# A31T21x register map
Vendor: ABOV Semiconductor Co., Ltd.; Series: A31T21x; File version: 1.0
CPU: CM0PLUS r0p1, little endian, no MPU, no FPU, VTOR, 2 interrupt priority bits
Registers are 32-bit, read-write, reset 0x0 unless marked. A register's access mark holds for its fields unless they carry their own. Offsets are from the block's base; [hi:lo] are bit positions.

## UART0 — UNIVERSAL ASYNCHRONOUS RECEIVER/TRANSMITTER
Base 0x40004000
Same registers: UART1 0x40004100
0x00 RBR ro — Receive Buffer Register
  [7:0] RBR — recevied/transmit data
0x00 THR wo — Transmit Data Hold Register
  [7:0] THR — recevied/transmit data
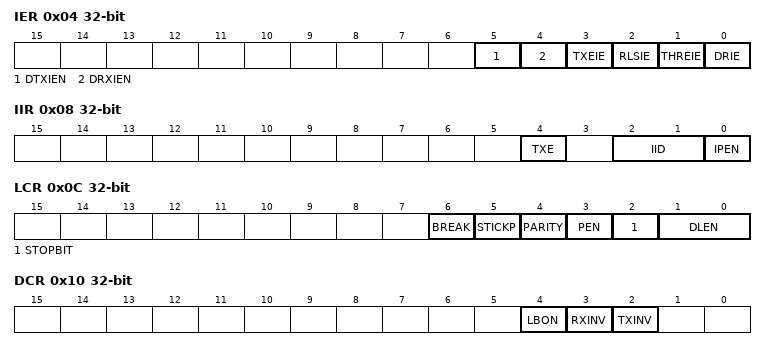
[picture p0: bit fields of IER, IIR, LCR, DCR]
0x04 IER — UART Interrupt Enable Register
  [5] DTXIEN — DMA transmit done interrupt enable
  [4] DRXIEN — DMA Receiver line status interrupt enable
  [3] TXEIE — Transmit Register Empty Interrupt Enable
  [2] RLSIE — receiver line status interrupt enable
  [1] THREIE — Transmit holding register empty interrupt enable
  [0] DRIE — Data receive interrupt enable
0x08 IIR — UART Interrupt ID Register
  [4] TXE — Interrupt source ID
  [2:1] IID — Interrupt source ID
  [0] IPEN — Interrupt pending bit
0x0C LCR — UART Line Control Register
  [6] BREAK
  [5] STICKP — STICK
  [4] PARITY
  [3] PEN — parity bit transfer enable
  [2] STOPBIT
  [1:0] DLEN — Data length in one transfer word
0x10 DCR — UART Data Control Register
  [4] LBON — Local loopback test mode enable
  [3] RXINV — Rx Data Inversion selection
  [2] TXINV — TX Data Inversion selection
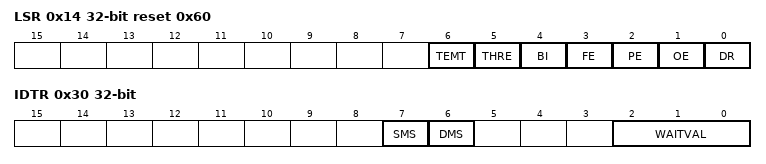
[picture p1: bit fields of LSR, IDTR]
0x14 LSR reset 0x60 — UART Line Status Register
  [6] TEMT — Transmit empty
  [5] THRE — Transmit holding register empty
  [4] BI — break condition indication bit
  [3] FE — frame error
  [2] PE — parity error
  [1] OE — overrun error
  [0] DR — Data recevied
0x20 BDR — Baud rate Divisor Latch Register
  [15:0] BDR — baudrate setting
0x24 BFR — Baud rate Fraction Counter Register
  [7:0] BFR — Fraction counter value
0x30 IDTR — Inter-frame Delay Time Register
  [7] SMS — Start Bit Multi Sampling Enable bit
  [6] DMS — Data Bit Multi sampling enable
  [2:0] WAITVAL — wait time is decied by this value

## SPI20 — Serial Peripheral Interface Bus
Base 0x40004C00
Same registers: SPI21 0x40004D00
0x00 TDR wo — SPI2 n Transmit Data Register
  [16:0] TDR — Transmit Data Bit
0x00 RDR ro — SPI n Received Data Register
  [16:0] RDR — Received Data Bit
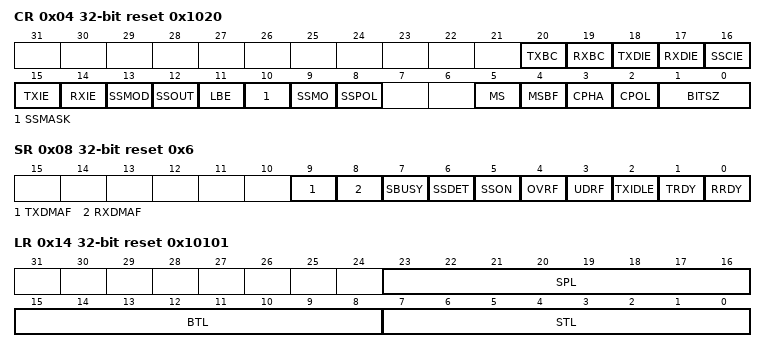
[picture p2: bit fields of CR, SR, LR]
0x04 CR reset 0x1020 — SPI Control Register
  [20] TXBC — Tx Buffer Clear Bit
  [19] RXBC — Rx Buffer Clear Bit
  [18] TXDIE — DMA Tx Complete Interrupt Enable Bit
  [17] RXDIE — DMA Rx Complete Interrupt Enable Bit
  [16] SSCIE — SS Edge Changed Interrupt Enable Bit
  [15] TXIE — Transmit Interrupt Enable Bit
  [14] RXIE — Received Interrupt Enable Bit
  [13] SSMOD — SS Auto/Manual Output Selection Bit in Master Mode
  [12] SSOUT — SS Output Signal Control Bit
  [11] LBE — Loop-back Mode Selection Bit in Master Mode
  [10] SSMASK — SS Signal Masking in Slave Mode
  [9] SSMO — SS Output Signal Selection Bit
  [8] SSPOL — SS Signal Polarity Selection Bit
  [5] MS — Master/Slave Selection Bit
  [4] MSBF — MSB/LSB Transmit Advance Selection Bit
  [3] CPHA — SPI Clock Phase Bit
  [2] CPOL — SPI Clock Polarity Bit
  [1:0] BITSZ — Transmit/Receive Bit Size Selection Bit
    0=8_BIT (Size is 8 bit); 1=9_BIT (Size is 9 bit); 2=16_BIT (Size is 16 bit); 3=17_BIT (Size is 17 bit)
0x08 SR reset 0x6 — SPI n Status Register
  [9] TXDMAF — DMA Transmit Operation Complete Flag
  [8] RXDMAF — DMA Received Operation Complete Flag
  [7] SBUSY ro — Transmit/Received Operating Flag
  [6] SSDET — SS Signal Rising or Falling Edge Detected Flag
  [5] SSON — SS Signal Status Flag
  [4] OVRF — Received Overrun Error Flag
  [3] UDRF — Transmit Underrun Error Flag
  [2] TXIDLE ro — Transmit Operating Flag
  [1] TRDY ro — Transmit Buffer Empty Flag
  [0] RRDY ro — Received Buffer Empty Flag
0x0C BR reset 0xFF — SPI n Baud Rate Register
  [15:0] BR — Baud Rate Setting Bit
0x10 EN — SPI n Enable Register
  [0] ENABLE — SPI Enable Bit
0x14 LR reset 0x10101 — SPI n Delay Length Register
  [23:16] SPL — SPI STOP Length Value Bit
  [15:8] BTL — SPI Burst Length Value Bit
  [7:0] STL — SPI Start Length Value Bit
